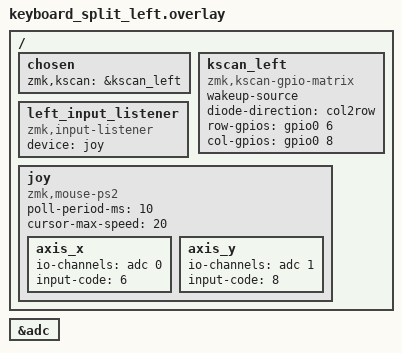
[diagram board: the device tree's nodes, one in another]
#include <dt-bindings/zmk/pointing.h>

&adc {
    status = "okay";
};

/ {
    chosen {
        zmk,kscan = &kscan_left;
    };

    kscan_left: kscan_left {
        compatible = "zmk,kscan-gpio-matrix";
        wakeup-source;
        diode-direction = "col2row";
        row-gpios = <&gpio0 6 (GPIO_ACTIVE_HIGH | GPIO_PULL_DOWN)>; 
        col-gpios = <&gpio0 8 GPIO_ACTIVE_HIGH>;
    };

    left_input_listener: left_input_listener {
        compatible = "zmk,input-listener";
        device = <&joy>; 
    };

    joy: joy {
        compatible = "zmk,mouse-ps2";
        poll-period-ms = <10>;
        cursor-max-speed = <20>; 
        axis_x {
            io-channels = <&adc 0>; 
            input-code = <6>; // REL_HWHEEL
        };
        axis_y {
            io-channels = <&adc 1>; 
            input-code = <8>; // REL_WHEEL
        };
    };
};
